# LOOP_MUX register map
Vendor: Texas Instruments
Peripheral module from a debugger description file (folder ucd3138128A).
Registers are 32-bit, access not given, no defined reset value unless marked. A register's access mark holds for its fields unless they carry their own. Offsets are as the file gives them; lines under a group give offsets from that group; [hi:lo] are bit positions; {n}, {i} and the like mark numbered series; 'fields as' and 'values as' point back to an identical list; <NAME> marks a mode.

## LOOPMUX
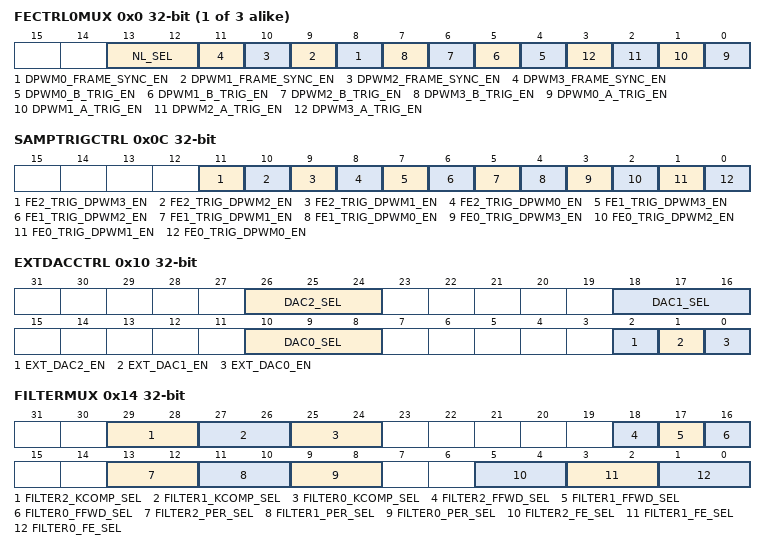
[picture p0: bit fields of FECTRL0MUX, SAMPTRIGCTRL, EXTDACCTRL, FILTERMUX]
{0x0+4i} FECTRL{i}MUX (i=0..2) — Front End Control {i} Mux Register
  [13:12] NL_SEL rw — Front End NL Limit Select
  [n+8] DPWM{n}_FRAME_SYNC_EN rw (n=0..3) — Front End DPWM3 Frame Sync Enable
  [n+4] DPWM{n}_B_TRIG_EN rw (n=0..3) — Front End DPWM{n} PWM-B Trig Enable
  [n] DPWM{n}_A_TRIG_EN rw (n=0..3) — Front End DPWM{n} PWM-A Trig Enable
0x0C SAMPTRIGCTRL — Sample Trigger Control Register
  [11] FE2_TRIG_DPWM3_EN rw — Front End 2 DPWM 3 Trig Enable
  [10] FE2_TRIG_DPWM2_EN rw — Front End 2 DPWM 2 Trig Enable
  [9] FE2_TRIG_DPWM1_EN rw — Front End 2 DPWM 1 Trig Enable
  [8] FE2_TRIG_DPWM0_EN rw — Front End 2 DPWM 1 Trig Enable
  [7] FE1_TRIG_DPWM3_EN rw — Front End 1 DPWM 3 Trig Enable
  [6] FE1_TRIG_DPWM2_EN rw — Front End 1 DPWM 2 Trig Enable
  [5] FE1_TRIG_DPWM1_EN rw — Front End 1 DPWM 1 Trig Enable
  [4] FE1_TRIG_DPWM0_EN rw — Front End 1 DPWM 1 Trig Enable
  [3] FE0_TRIG_DPWM3_EN rw — Front End 0 DPWM 3 Trig Enable
  [2] FE0_TRIG_DPWM2_EN rw — Front End 0 DPWM 2 Trig Enable
  [1] FE0_TRIG_DPWM1_EN rw — Front End 0 DPWM 1 Trig Enable
  [0] FE0_TRIG_DPWM0_EN rw — Front End 0 DPWM 1 Trig Enable
0x10 EXTDACCTRL — External DAC Control Register
  [26:24] DAC2_SEL rw — DAC 2 Select
  [18:16] DAC1_SEL rw — DAC 1 Select
  [10:8] DAC0_SEL rw — DAC 0 Select
  [2] EXT_DAC2_EN rw — External DAC 2 Enable
  [1] EXT_DAC1_EN rw — External DAC 1 Enable
  [0] EXT_DAC0_EN rw — External DAC 0 Enable
0x14 FILTERMUX
  [29:28] FILTER2_KCOMP_SEL rw — Filter 2 KComp Select
  [27:26] FILTER1_KCOMP_SEL rw — Filter 1 KComp Select
  [25:24] FILTER0_KCOMP_SEL rw — Filter 0 KComp Select
  [18] FILTER2_FFWD_SEL rw — Filter 2 Feedforward Select
  [17] FILTER1_FFWD_SEL rw — Filter 1 Feedforward Select
  [16] FILTER0_FFWD_SEL rw — Filter 0 Feedforward Select
  [13:12] FILTER2_PER_SEL rw — Filter 2 Switching Period Select
  [11:10] FILTER1_PER_SEL rw — Filter 1 Switching Period Select
  [9:8] FILTER0_PER_SEL rw — Filter 0 Switching Period Select
  [5:4] FILTER2_FE_SEL rw — Filter 2 Front End Select
  [3:2] FILTER1_FE_SEL rw — Filter 1 Front End Select
  [1:0] FILTER0_FE_SEL rw — Filter 0 Front End Select
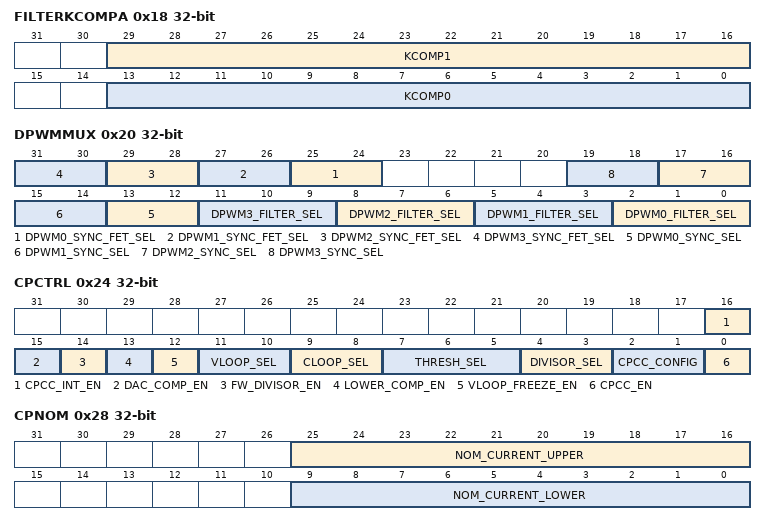
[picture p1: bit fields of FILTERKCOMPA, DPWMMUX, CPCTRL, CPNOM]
0x18 FILTERKCOMPA
  [29:16] KCOMP1 rw — KCOMP1 Value
  [13:0] KCOMP0 rw — KCOMP0 Value
0x1C FILTERKCOMPB
  [13:0] KCOMP2 rw — KCOMP2 Value
0x20 DPWMMUX
  [2n+25:2n+24] DPWM{n}_SYNC_FET_SEL rw (n=0..3) — DPWM{n} Sync Fet Ramp Select
  [2n+13:2n+12] DPWM{n}_SYNC_SEL rw (n=0..3) — DPWM{n} Sync Select
  [3n+2:3n] DPWM{n}_FILTER_SEL rw (n=0..3) — DPWM{n} Filter Select
0x24 CPCTRL — Constant Power Control Register
  [16] CPCC_INT_EN rw — Constant Power/Current Interrupt Enable
  [15] DAC_COMP_EN rw — Enables DAC Setpoint comparison
  [14] FW_DIVISOR_EN rw — Enable Firwmare Divisor for Constant Power Calculation
  [13] LOWER_COMP_EN rw — Enable comparison of duty cycle in loop switching
  [12] VLOOP_FREEZE_EN rw — Enables freeze of Voltage Loop Integration in CC Mode
  [11:10] VLOOP_SEL rw — Select Voltage Loop for Loop Switching
  [9:8] CLOOP_SEL rw — Select Current Loop for Loop Switching
  [7:5] THRESH_SEL rw — Select Input Threshold for CPCC
  [4:3] DIVISOR_SEL rw — Select Divisor Value
  [2:1] CPCC_CONFIG rw — Constant Power/Current Configuration
  [0] CPCC_EN rw — Constant Power Constant Current Enable
0x28 CPNOM — Constant Power Nominal Threshold Register
  [25:16] NOM_CURRENT_UPPER rw — Nominal Current Upper Threshold
  [9:0] NOM_CURRENT_LOWER rw — Nominal Current Lower Threshold
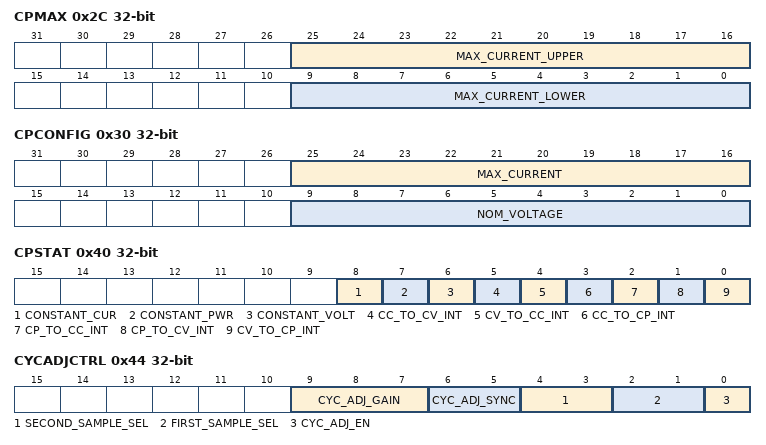
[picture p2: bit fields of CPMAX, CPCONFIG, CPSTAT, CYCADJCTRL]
0x2C CPMAX — Constant Power Maximum Threshold Register
  [25:16] MAX_CURRENT_UPPER rw — Maximum Current Upper Threshold
  [9:0] MAX_CURRENT_LOWER rw — Maximum Current Lower Threshold
0x30 CPCONFIG — Constant Power Configuration Register
  [25:16] MAX_CURRENT rw — Maximum Current
  [9:0] NOM_VOLTAGE rw — Nominal Voltage
0x34 CPMAXPWR — Constant Power Maximum Power Register
  [19:0] MAX_POWER rw — Maximum Power
0x38 CPINTTHRESH — Constant Power Integrator Threshold Register
  [23:0] INT_THRESH rw — Signed Integrator Threshold
0x3C CPFWDIVISOR — Constant Power Firmware Divisor Register
  [9:0] FW_DIVISOR rw — Firmware configurable divisor
0x40 CPSTAT — Constant Power Status Register
  [8] CONSTANT_CUR ro — Constant Current Mode Indication
  [7] CONSTANT_PWR ro — Constant Power Mode Indication
  [6] CONSTANT_VOLT ro — Constant Voltage Mode Indication
  [5] CC_TO_CV_INT ro — Constant Current to Voltage Interrupt
  [4] CV_TO_CC_INT ro — Constant Voltage to Current Interrupt
  [3] CC_TO_CP_INT ro — Constant Current to Power Interrupt
  [2] CP_TO_CC_INT ro — Constant Power to Current Interrupt
  [1] CP_TO_CV_INT ro — Constant Power to Voltage Interrupt
  [0] CV_TO_CP_INT ro — Constant Voltage to Power Interrupt
0x44 CYCADJCTRL — Cycle Adjustment Control
  [9:7] CYC_ADJ_GAIN rw — Cycle Adjustment Gain
  [6:5] CYC_ADJ_SYNC rw — Cycle Adjustment Sync
  [4:3] SECOND_SAMPLE_SEL rw — Second Cycle Adjustment Select
  [2:1] FIRST_SAMPLE_SEL rw — First Cycle Adjustment Select
  [0] CYC_ADJ_EN rw — Cycle Adjustment Enable
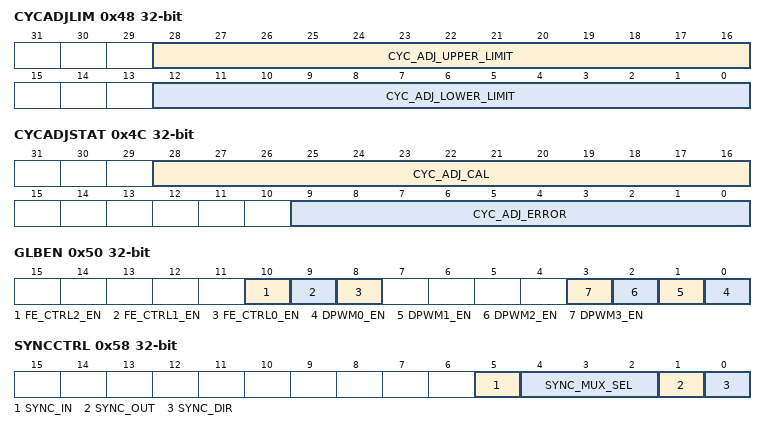
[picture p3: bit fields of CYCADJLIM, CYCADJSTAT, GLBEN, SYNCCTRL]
0x48 CYCADJLIM — Cycle Adjustment Limit Register
  [28:16] CYC_ADJ_UPPER_LIMIT rw — Cycle Adjustment Upper Limit
  [12:0] CYC_ADJ_LOWER_LIMIT rw — Cycle Adjustment Lower Limit
0x4C CYCADJSTAT — Cycle Adjustment Status Register
  [28:16] CYC_ADJ_CAL ro — Cycle Adjustment Calculation
  [9:0] CYC_ADJ_ERROR ro — Cycle Adjustment Error
0x50 GLBEN — Global Enable Register
  [10] FE_CTRL2_EN rw — Global Enable for Front End Control 2
  [9] FE_CTRL1_EN rw — Global Enable for Front End Control 1
  [8] FE_CTRL0_EN rw — Global Enable for Front End Control 0
  [n] DPWM{n}_EN rw (n=0..3) — Global Enable for DPWM Module {n}
0x54 PWMGLBPER — PWM Global Period Register
  [17:4] PRD ro — Global DPWM Period Value
0x58 SYNCCTRL — Sync Control Register
  [5] SYNC_IN ro — Sync pin value
  [4:2] SYNC_MUX_SEL rw — Sync Select
  [1] SYNC_OUT rw — Sync GPIO Value
  [0] SYNC_DIR rw — Sync Pin Direction
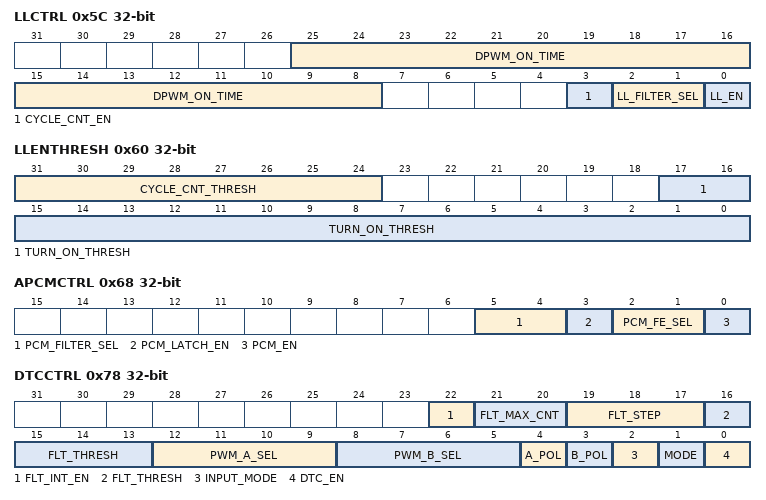
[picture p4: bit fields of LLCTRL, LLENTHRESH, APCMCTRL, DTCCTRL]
0x5C LLCTRL — Light Load Control Register
  [25:8] DPWM_ON_TIME rw — DPWM On Time during Light Load Mode
  [3] CYCLE_CNT_EN rw — Cycle Counter Enable
  [2:1] LL_FILTER_SEL rw — Light Load Filter Select
  [0] LL_EN rw — Light Load Enable
0x60 LLENTHRESH — Light Load Enable Threshold Register
  [31:24] CYCLE_CNT_THRESH rw — Switching Cycle Counter Threshold for turning on burst mode
  [17:0] TURN_ON_THRESH rw — Filter Data Threshold to turn on burst mode
0x64 LLDISTHRESH — Light Load Disable Threshold Register
  [17:0] TURN_OFF_THRESH rw — Filter Data Threshold to turn off burst mode
0x68 APCMCTRL — Analog Peak Current Mode Control Register
  [5:4] PCM_FILTER_SEL rw — PCM Filter Select
  [3] PCM_LATCH_EN rw — PCM Latch Enable
  [2:1] PCM_FE_SEL rw — Analog Peak Current Front End Select
  [0] PCM_EN rw — Analog Peak Current Mode Enable
0x78 DTCCTRL — DTC Control Register
  [22] FLT_INT_EN rw
  [21:20] FLT_MAX_CNT rw
  [19:17] FLT_STEP rw
  [16:13] FLT_THRESH rw
  [12:9] PWM_A_SEL rw
  [8:5] PWM_B_SEL rw
  [4] A_POL rw
  [3] B_POL rw
  [2] INPUT_MODE rw
  [1] MODE rw — Changed to MODE. 10/17/2014 AC
  [0] DTC_EN rw
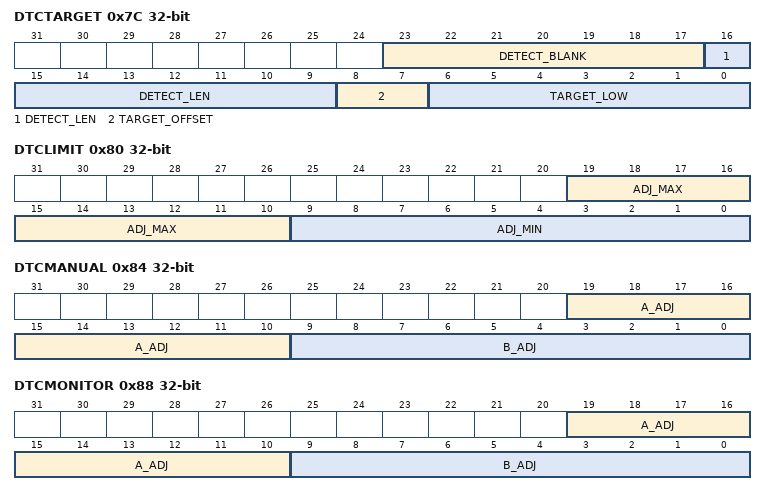
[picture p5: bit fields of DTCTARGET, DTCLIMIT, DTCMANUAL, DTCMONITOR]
0x7C DTCTARGET
  [23:17] DETECT_BLANK rw, [16:9] DETECT_LEN rw, [8:7] TARGET_OFFSET rw, [6:0] TARGET_LOW rw
0x80 DTCLIMIT
  [19:10] ADJ_MAX rw, [9:0] ADJ_MIN rw
0x84 DTCMANUAL — DTC Manual Control Register
  [19:10] A_ADJ rw, [9:0] B_ADJ rw
0x88 DTCMONITOR
  [19:10] A_ADJ ro, [9:0] B_ADJ ro
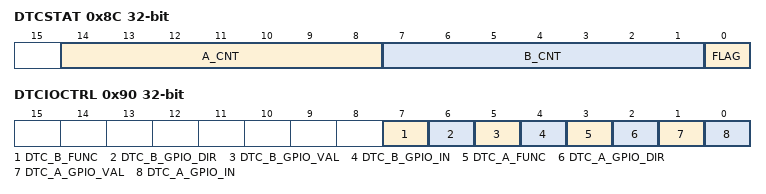
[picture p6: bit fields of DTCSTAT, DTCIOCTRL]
0x8C DTCSTAT — DTC Status Register
  [14:8] A_CNT rw, [7:1] B_CNT rw, [0] FLAG rw
0x90 DTCIOCTRL
  [7] DTC_B_FUNC rw — DTC B FUNC Mode
  [6] DTC_B_GPIO_DIR rw
  [5] DTC_B_GPIO_VAL rw
  [4] DTC_B_GPIO_IN rw
  [3] DTC_A_FUNC rw — DTC A FUNC Mode
  [2] DTC_A_GPIO_DIR rw
  [1] DTC_A_GPIO_VAL rw
  [0] DTC_A_GPIO_IN rw
